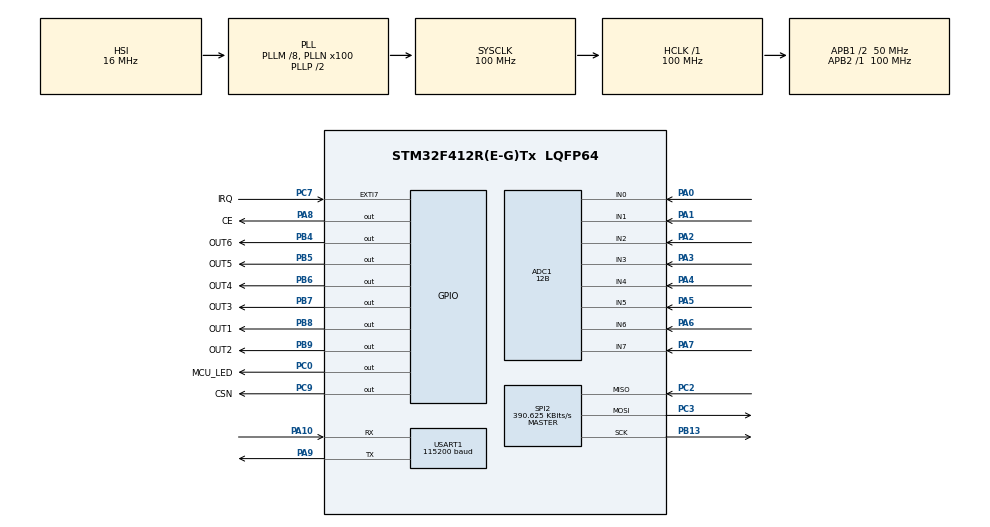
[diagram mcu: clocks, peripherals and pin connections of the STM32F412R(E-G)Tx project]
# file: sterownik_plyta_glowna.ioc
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ADC1.Channel-0\#ChannelRegularConversion=ADC_CHANNEL_0
ADC1.Channel-1\#ChannelRegularConversion=ADC_CHANNEL_2
ADC1.Channel-2\#ChannelRegularConversion=ADC_CHANNEL_1
ADC1.Channel-3\#ChannelRegularConversion=ADC_CHANNEL_3
ADC1.Channel-4\#ChannelRegularConversion=ADC_CHANNEL_4
ADC1.Channel-5\#ChannelRegularConversion=ADC_CHANNEL_5
ADC1.Channel-6\#ChannelRegularConversion=ADC_CHANNEL_6
ADC1.Channel-7\#ChannelRegularConversion=ADC_CHANNEL_7
ADC1.ClockPrescaler=ADC_CLOCK_SYNC_PCLK_DIV8
ADC1.ContinuousConvMode=ENABLE
ADC1.DMAContinuousRequests=ENABLE
ADC1.EnableAnalogWatchDog=true
ADC1.NbrOfConversion=8
ADC1.NbrOfConversionFlag=1
ADC1.Rank-0\#ChannelRegularConversion=1
ADC1.Rank-1\#ChannelRegularConversion=2
ADC1.Rank-2\#ChannelRegularConversion=3
ADC1.Rank-3\#ChannelRegularConversion=4
ADC1.Rank-4\#ChannelRegularConversion=5
ADC1.Rank-5\#ChannelRegularConversion=6
ADC1.Rank-6\#ChannelRegularConversion=7
ADC1.Rank-7\#ChannelRegularConversion=8
ADC1.Resolution=ADC_RESOLUTION_12B
ADC1.SamplingTime-0\#ChannelRegularConversion=ADC_SAMPLETIME_28CYCLES
ADC1.SamplingTime-1\#ChannelRegularConversion=ADC_SAMPLETIME_28CYCLES
ADC1.SamplingTime-2\#ChannelRegularConversion=ADC_SAMPLETIME_84CYCLES
ADC1.SamplingTime-3\#ChannelRegularConversion=ADC_SAMPLETIME_84CYCLES
ADC1.SamplingTime-4\#ChannelRegularConversion=ADC_SAMPLETIME_84CYCLES
ADC1.SamplingTime-5\#ChannelRegularConversion=ADC_SAMPLETIME_84CYCLES
ADC1.SamplingTime-6\#ChannelRegularConversion=ADC_SAMPLETIME_84CYCLES
ADC1.SamplingTime-7\#ChannelRegularConversion=ADC_SAMPLETIME_84CYCLES
ADC1.ScanConvMode=ENABLE
ADC1.master=1
Dma.ADC1.0.Direction=DMA_PERIPH_TO_MEMORY
Dma.ADC1.0.FIFOMode=DMA_FIFOMODE_DISABLE
Dma.ADC1.0.Instance=DMA2_Stream0
Dma.ADC1.0.MemDataAlignment=DMA_MDATAALIGN_HALFWORD
Dma.ADC1.0.MemInc=DMA_MINC_ENABLE
Dma.ADC1.0.Mode=DMA_CIRCULAR
Dma.ADC1.0.PeriphDataAlignment=DMA_PDATAALIGN_HALFWORD
Dma.ADC1.0.PeriphInc=DMA_PINC_DISABLE
Dma.ADC1.0.Priority=DMA_PRIORITY_MEDIUM
Dma.Request0=ADC1
Dma.Request1=USART1_RX
Dma.Request2=USART1_TX
Dma.USART1_RX.1.Direction=DMA_PERIPH_TO_MEMORY
Dma.USART1_RX.1.FIFOMode=DMA_FIFOMODE_DISABLE
Dma.USART1_RX.1.Instance=DMA2_Stream2
Dma.USART1_RX.1.MemDataAlignment=DMA_MDATAALIGN_BYTE
Dma.USART1_RX.1.MemInc=DMA_MINC_ENABLE
Dma.USART1_RX.1.Mode=DMA_NORMAL
Dma.USART1_RX.1.PeriphDataAlignment=DMA_PDATAALIGN_BYTE
Dma.USART1_RX.1.PeriphInc=DMA_PINC_DISABLE
Dma.USART1_RX.1.Priority=DMA_PRIORITY_VERY_HIGH
Dma.USART1_TX.2.Direction=DMA_MEMORY_TO_PERIPH
Dma.USART1_TX.2.FIFOMode=DMA_FIFOMODE_DISABLE
Dma.USART1_TX.2.Instance=DMA2_Stream7
Dma.USART1_TX.2.MemDataAlignment=DMA_MDATAALIGN_BYTE
Dma.USART1_TX.2.MemInc=DMA_MINC_ENABLE
Dma.USART1_TX.2.Mode=DMA_NORMAL
Dma.USART1_TX.2.PeriphDataAlignment=DMA_PDATAALIGN_BYTE
Dma.USART1_TX.2.PeriphInc=DMA_PINC_DISABLE
Dma.USART1_TX.2.Priority=DMA_PRIORITY_VERY_HIGH
Mcu.Family=STM32F4
Mcu.Name=STM32F412R(E-G)Tx
Mcu.Package=LQFP64
NVIC.ADC_IRQn=true\:0\:0\:false\:false\:true\:true\:true\:true
NVIC.DMA2_Stream0_IRQn=true\:0\:0\:false\:false\:true\:false\:true\:true
NVIC.DMA2_Stream2_IRQn=true\:0\:0\:false\:false\:true\:false\:true\:true
NVIC.DMA2_Stream7_IRQn=true\:0\:0\:false\:false\:true\:false\:true\:true
NVIC.EXTI9_5_IRQn=true\:0\:0\:false\:false\:true\:true\:true\:true
NVIC.PriorityGroup=NVIC_PRIORITYGROUP_4
NVIC.SPI2_IRQn=true\:0\:0\:false\:false\:true\:true\:true\:true
NVIC.TIM1_TRG_COM_TIM11_IRQn=true\:0\:0\:false\:false\:true\:true\:true\:true
NVIC.TIM6_IRQn=true\:0\:0\:false\:false\:true\:true\:true\:true
NVIC.TIM7_IRQn=true\:0\:0\:false\:false\:true\:true\:true\:true
NVIC.TIM8_TRG_COM_TIM14_IRQn=true\:0\:0\:false\:false\:true\:true\:true\:true
NVIC.TIM8_UP_TIM13_IRQn=true\:0\:0\:false\:false\:true\:true\:true\:true
NVIC.USART1_IRQn=true\:0\:0\:false\:false\:true\:true\:true\:true
PA0.Signal=ADCx_IN0
PA1.Signal=ADCx_IN1
PA10.Mode=Asynchronous
PA10.Signal=USART1_RX
PA2.Signal=ADCx_IN2
PA3.Signal=ADCx_IN3
PA4.Signal=ADCx_IN4
PA5.Signal=ADCx_IN5
PA6.Signal=ADCx_IN6
PA7.Signal=ADCx_IN7
PA8.GPIO_Label=CE
PA8.GPIO_Speed=GPIO_SPEED_FREQ_VERY_HIGH
PA8.Signal=GPIO_Output
PA9.Mode=Asynchronous
PA9.Signal=USART1_TX
PB13.Mode=Full_Duplex_Master
PB13.Signal=SPI2_SCK
PB4.GPIO_Label=OUT6
PB4.Signal=GPIO_Output
PB5.GPIO_Label=OUT5
PB5.Signal=GPIO_Output
PB6.GPIO_Label=OUT4
PB6.Signal=GPIO_Output
PB7.GPIO_Label=OUT3
PB7.Signal=GPIO_Output
PB8.GPIO_Label=OUT1
PB8.Signal=GPIO_Output
PB9.GPIO_Label=OUT2
PB9.Signal=GPIO_Output
PC0.GPIO_Label=MCU_LED
PC0.Signal=GPIO_Output
PC2.Mode=Full_Duplex_Master
PC2.Signal=SPI2_MISO
PC3.Mode=Full_Duplex_Master
PC3.Signal=SPI2_MOSI
PC7.GPIO_Label=IRQ
PC7.GPIO_ModeDefaultEXTI=GPIO_MODE_IT_FALLING
PC7.GPIO_PuPd=GPIO_NOPULL
PC7.Signal=GPXTI7
PC9.GPIO_Label=CSN
PC9.GPIO_Speed=GPIO_SPEED_FREQ_VERY_HIGH
PC9.PinState=GPIO_PIN_SET
PC9.Signal=GPIO_Output
ProjectManager.HeapSize=0x200
ProjectManager.StackSize=0x400
ProjectManager.TargetToolchain=STM32CubeIDE
RCC.AHBFreq_Value=100000000
RCC.APB1CLKDivider=RCC_HCLK_DIV2
RCC.APB1Freq_Value=50000000
RCC.APB1TimFreq_Value=100000000
RCC.APB2Freq_Value=100000000
RCC.APB2TimFreq_Value=100000000
RCC.CortexFreq_Value=100000000
RCC.HCLKFreq_Value=100000000
RCC.PLLM=8
RCC.PLLN=100
RCC.SYSCLKFreq_VALUE=100000000
RCC.SYSCLKSource=RCC_SYSCLKSOURCE_PLLCLK
RCC.USBFreq_Value=100000000
RCC.VCOOutputFreq_Value=200000000
SH.ADCx_IN0.0=ADC1_IN0,IN0
SH.ADCx_IN1.0=ADC1_IN1,IN1
SH.ADCx_IN2.0=ADC1_IN2,IN2
SH.ADCx_IN3.0=ADC1_IN3,IN3
SH.ADCx_IN4.0=ADC1_IN4,IN4
SH.ADCx_IN5.0=ADC1_IN5,IN5
SH.ADCx_IN6.0=ADC1_IN6,IN6
SH.ADCx_IN7.0=ADC1_IN7,IN7
SPI2.BaudRatePrescaler=SPI_BAUDRATEPRESCALER_128
SPI2.CalculateBaudRate=390.625 KBits/s
SPI2.Direction=SPI_DIRECTION_2LINES
SPI2.Mode=SPI_MODE_MASTER
SPI2.VirtualType=VM_MASTER
TIM11.Period=65358
TIM11.Prescaler=15299
TIM13.Period=62499
TIM13.Prescaler=799
TIM14.Period=49999
TIM14.Prescaler=200
TIM6.Period=62499
TIM6.Prescaler=1599
TIM7.Period=49999
TIM7.Prescaler=1
USART1.BaudRate=115200
USART1.VirtualMode=VM_ASYNC
VP_TIM10_VS_ClockSourceINT.Mode=Enable_Timer
VP_TIM11_VS_ClockSourceINT.Mode=Enable_Timer
VP_TIM13_VS_ClockSourceINT.Mode=Enable_Timer
VP_TIM14_VS_ClockSourceINT.Mode=Enable_Timer
VP_TIM6_VS_ClockSourceINT.Mode=Enable_Timer
VP_TIM7_VS_ClockSourceINT.Mode=Enable_Timer
board=custom

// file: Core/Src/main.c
/* USER CODE BEGIN Header */
/**
  ******************************************************************************
  * @file           : main.c
  * @brief          : Main program body
  ******************************************************************************
  * @attention
  *
  * Copyright (c) 2025 STMicroelectronics.
  * All rights reserved.
  *
  * This software is licensed under terms that can be found in the LICENSE file
  * in the root directory of this software component.
  * If no LICENSE file comes with this software, it is provided AS-IS.
  *
  ******************************************************************************
  */
/* USER CODE END Header */
#include "main.h"
#include "adc.h"
#include "dma.h"
#include "spi.h"
#include "tim.h"
#include "usart.h"
#include "gpio.h"

/* USER CODE BEGIN Includes */
#include "init.h"
#include "cycle.h"
#include <string.h>
#include <stdio.h>
#include "nrf24l01p.h"
/* USER CODE END Includes */

void SystemClock_Config(void);

int main(void)
{

  /* MCU Configuration--------------------------------------------------------*/

  /* Reset of all peripherals, Initializes the Flash interface and the Systick. */
  HAL_Init();

  /* Configure the system clock */
  SystemClock_Config();

  /* Initialize all configured peripherals */
  MX_GPIO_Init();
  MX_DMA_Init();
  MX_ADC1_Init();
  MX_TIM10_Init();
  MX_TIM14_Init();
  MX_USART1_UART_Init();
  MX_SPI2_Init();
  MX_TIM13_Init();
  MX_TIM6_Init();
  MX_TIM7_Init();
  MX_TIM11_Init();
  /* USER CODE BEGIN 2 */

  init();

  /* USER CODE END 2 */

  /* Infinite loop */
  /* USER CODE BEGIN WHILE */
  while (1)
  {

	  cycle();

    /* USER CODE END WHILE */

  }
}

void SystemClock_Config(void)
{
  RCC_OscInitTypeDef RCC_OscInitStruct = {0};
  RCC_ClkInitTypeDef RCC_ClkInitStruct = {0};

  /** Configure the main internal regulator output voltage
  */
  __HAL_RCC_PWR_CLK_ENABLE();
  __HAL_PWR_VOLTAGESCALING_CONFIG(PWR_REGULATOR_VOLTAGE_SCALE1);

  /** Initializes the RCC Oscillators according to the specified parameters
  * in the RCC_OscInitTypeDef structure.
  */
  RCC_OscInitStruct.OscillatorType = RCC_OSCILLATORTYPE_HSI;
  RCC_OscInitStruct.HSIState = RCC_HSI_ON;
  RCC_OscInitStruct.HSICalibrationValue = RCC_HSICALIBRATION_DEFAULT;
  RCC_OscInitStruct.PLL.PLLState = RCC_PLL_ON;
  RCC_OscInitStruct.PLL.PLLSource = RCC_PLLSOURCE_HSI;
  RCC_OscInitStruct.PLL.PLLM = 8;
  RCC_OscInitStruct.PLL.PLLN = 100;
  RCC_OscInitStruct.PLL.PLLP = RCC_PLLP_DIV2;
  RCC_OscInitStruct.PLL.PLLQ = 2;
  RCC_OscInitStruct.PLL.PLLR = 2;
  if (HAL_RCC_OscConfig(&RCC_OscInitStruct) != HAL_OK)
  {
    Error_Handler();
  }

  /** Initializes the CPU, AHB and APB buses clocks
  */
  RCC_ClkInitStruct.ClockType = RCC_CLOCKTYPE_HCLK|RCC_CLOCKTYPE_SYSCLK
                              |RCC_CLOCKTYPE_PCLK1|RCC_CLOCKTYPE_PCLK2;
  RCC_ClkInitStruct.SYSCLKSource = RCC_SYSCLKSOURCE_PLLCLK;
  RCC_ClkInitStruct.AHBCLKDivider = RCC_SYSCLK_DIV1;
  RCC_ClkInitStruct.APB1CLKDivider = RCC_HCLK_DIV2;
  RCC_ClkInitStruct.APB2CLKDivider = RCC_HCLK_DIV1;

  if (HAL_RCC_ClockConfig(&RCC_ClkInitStruct, FLASH_LATENCY_3) != HAL_OK)
  {
    Error_Handler();
  }
}

void Error_Handler(void)
{
  __disable_irq();
  while (1)
  {
  }
}
